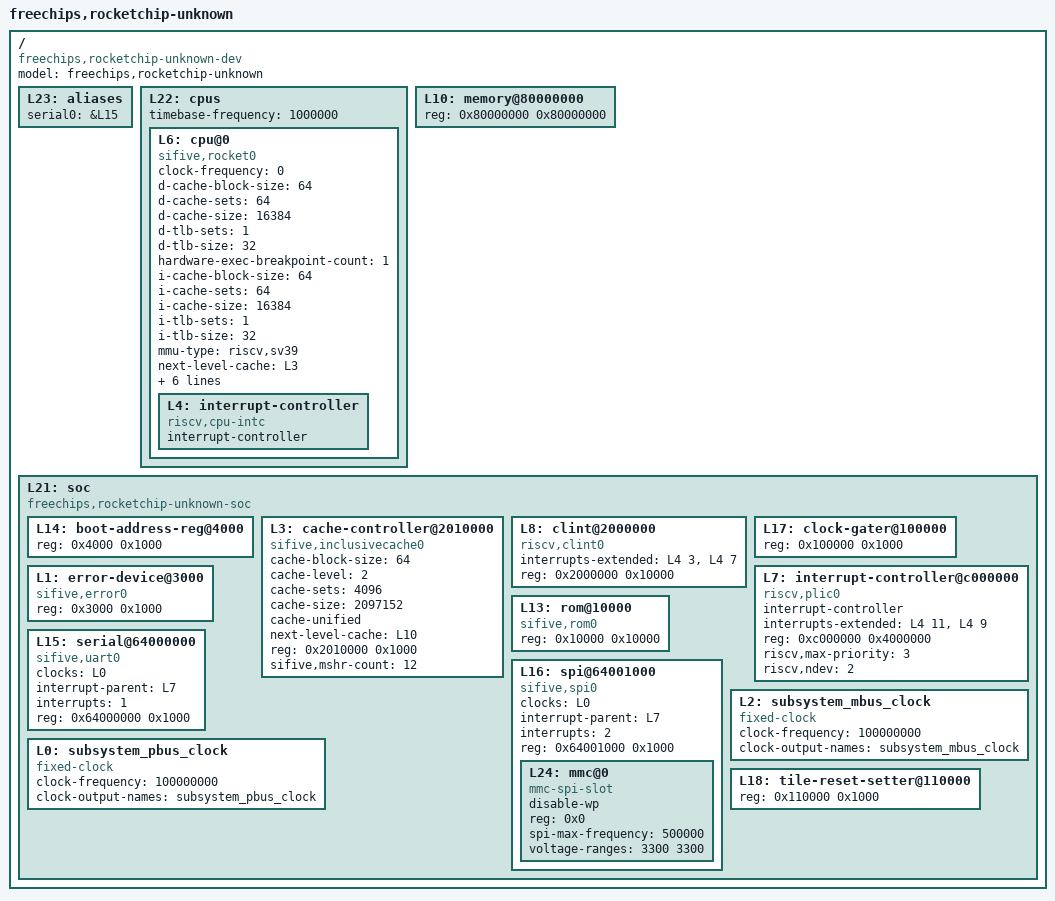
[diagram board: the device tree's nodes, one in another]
/dts-v1/;

/ {
	#address-cells = <1>;
	#size-cells = <1>;
	compatible = "freechips,rocketchip-unknown-dev";
	model = "freechips,rocketchip-unknown";
	L23: aliases {
		serial0 = &L15;
	};
	L22: cpus {
		#address-cells = <1>;
		#size-cells = <0>;
		timebase-frequency = <1000000>;
		L6: cpu@0 {
			clock-frequency = <0>;
			compatible = "sifive,rocket0", "riscv";
			d-cache-block-size = <64>;
			d-cache-sets = <64>;
			d-cache-size = <16384>;
			d-tlb-sets = <1>;
			d-tlb-size = <32>;
			device_type = "cpu";
			hardware-exec-breakpoint-count = <1>;
			i-cache-block-size = <64>;
			i-cache-sets = <64>;
			i-cache-size = <16384>;
			i-tlb-sets = <1>;
			i-tlb-size = <32>;
			mmu-type = "riscv,sv39";
			next-level-cache = <&L3>;
			reg = <0x0>;
			riscv,isa = "rv64imafdc";
			riscv,pmpgranularity = <4>;
			riscv,pmpregions = <8>;
			status = "okay";
			timebase-frequency = <1000000>;
			tlb-split;
			L4: interrupt-controller {
				#interrupt-cells = <1>;
				compatible = "riscv,cpu-intc";
				interrupt-controller;
			};
		};
	};
	L10: memory@80000000 {
		device_type = "memory";
		reg = <0x80000000 0x80000000>;
	};
	L21: soc {
		#address-cells = <1>;
		#size-cells = <1>;
		compatible = "freechips,rocketchip-unknown-soc", "simple-bus";
		ranges;
		L14: boot-address-reg@4000 {
			reg = <0x4000 0x1000>;
			reg-names = "control";
		};
		L3: cache-controller@2010000 {
			cache-block-size = <64>;
			cache-level = <2>;
			cache-sets = <4096>;
			cache-size = <2097152>;
			cache-unified;
			compatible = "sifive,inclusivecache0", "cache";
			next-level-cache = <&L10>;
			reg = <0x2010000 0x1000>;
			reg-names = "control";
			sifive,mshr-count = <12>;
		};
		L8: clint@2000000 {
			compatible = "riscv,clint0";
			interrupts-extended = <&L4 3 &L4 7>;
			reg = <0x2000000 0x10000>;
			reg-names = "control";
		};
		L17: clock-gater@100000 {
			reg = <0x100000 0x1000>;
			reg-names = "control";
		};
		L1: error-device@3000 {
			compatible = "sifive,error0";
			reg = <0x3000 0x1000>;
		};
		L7: interrupt-controller@c000000 {
			#interrupt-cells = <1>;
			compatible = "riscv,plic0";
			interrupt-controller;
			interrupts-extended = <&L4 11 &L4 9>;
			reg = <0xc000000 0x4000000>;
			reg-names = "control";
			riscv,max-priority = <3>;
			riscv,ndev = <2>;
		};
		L13: rom@10000 {
			compatible = "sifive,rom0";
			reg = <0x10000 0x10000>;
			reg-names = "mem";
		};
		L15: serial@64000000 {
			clocks = <&L0>;
			compatible = "sifive,uart0";
			interrupt-parent = <&L7>;
			interrupts = <1>;
			reg = <0x64000000 0x1000>;
			reg-names = "control";
		};
		L16: spi@64001000 {
			#address-cells = <1>;
			#size-cells = <0>;
			clocks = <&L0>;
			compatible = "sifive,spi0";
			interrupt-parent = <&L7>;
			interrupts = <2>;
			reg = <0x64001000 0x1000>;
			reg-names = "control";
			L24: mmc@0 {
				compatible = "mmc-spi-slot";
				disable-wp;
				reg = <0x0>;
				spi-max-frequency = <500000>;
				voltage-ranges = <3300 3300>;
			};
		};
		L2: subsystem_mbus_clock {
			#clock-cells = <0>;
			clock-frequency = <100000000>;
			clock-output-names = "subsystem_mbus_clock";
			compatible = "fixed-clock";
		};
		L0: subsystem_pbus_clock {
			#clock-cells = <0>;
			clock-frequency = <100000000>;
			clock-output-names = "subsystem_pbus_clock";
			compatible = "fixed-clock";
		};
		L18: tile-reset-setter@110000 {
			reg = <0x110000 0x1000>;
			reg-names = "control";
		};
	};
};
